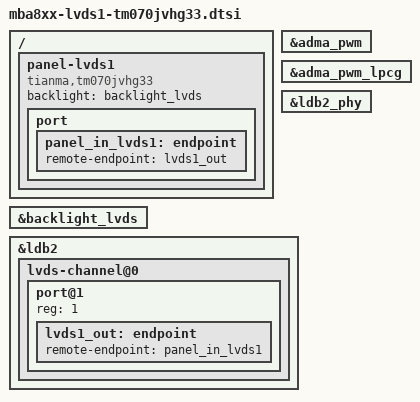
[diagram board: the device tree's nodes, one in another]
// SPDX-License-Identifier: (GPL-2.0-or-later OR MIT)
/*
 * Copyright 2021-2022 TQ-Systems GmbH
 * Author: Alexander Stein <linux@ew.tq-group.com>
 */

/ {
	panel-lvds1 {
		compatible = "tianma,tm070jvhg33";
		backlight = <&backlight_lvds>;
		status = "okay";

		port {
			panel_in_lvds1: endpoint {
				remote-endpoint = <&lvds1_out>;
			};
		};
	};
};

&adma_pwm {
	status = "okay";
};

&adma_pwm_lpcg {
	status = "okay";
};

&backlight_lvds {
	status = "okay";
};

&ldb2_phy {
	status = "okay";
};

&ldb2 {
	status = "okay";

	lvds-channel@0 {
		status = "okay";

		port@1 {
			reg = <1>;

			lvds1_out: endpoint {
				remote-endpoint = <&panel_in_lvds1>;
			};
		};
	};
};
